VERSION ""

NS_ :

BS_:

BU_: BRAKE STEERING THROTTLE FAULT

BO_ 112 BRAKE_ENABLE: 8 BRAKE
 SG_ brake_enable_magic : 0|16@1+ (1,0) [0|0] "" BRAKE
 SG_ brake_enable_reserved : 16|48@1+ (1,0) [0|0] "" BRAKE

BO_ 113 BRAKE_DISABLE: 8 BRAKE
 SG_ brake_disable_magic : 0|16@1+ (1,0) [0|0] "" BRAKE
 SG_ brake_disable_reserved : 16|48@1+ (1,0) [0|0] "" BRAKE

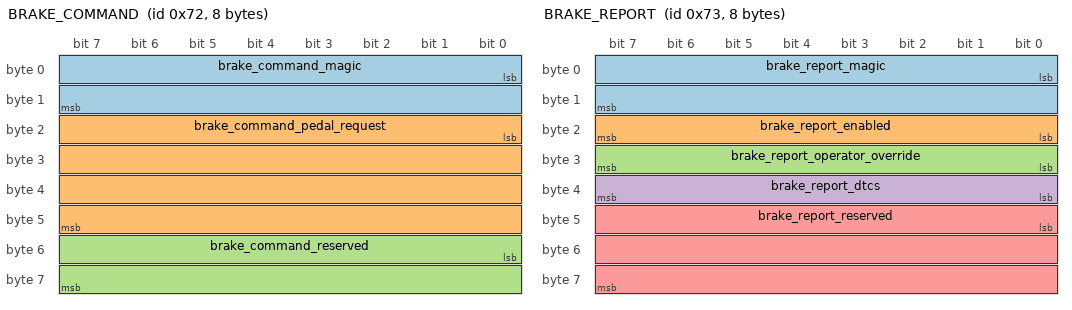
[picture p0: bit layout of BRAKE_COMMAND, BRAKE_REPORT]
BO_ 114 BRAKE_COMMAND: 8 BRAKE
 SG_ brake_command_magic : 0|16@1+ (1,0) [0|0] "" BRAKE
 SG_ brake_command_pedal_request : 16|32@1+ (1,0) [0|1] "" BRAKE
 SG_ brake_command_reserved : 48|16@1+ (1,0) [0|0] "" BRAKE

BO_ 115 BRAKE_REPORT: 8 BRAKE
 SG_ brake_report_magic : 0|16@1+ (1,0) [0|0] "" BRAKE
 SG_ brake_report_enabled : 16|8@1+ (1,0) [0|0] "" BRAKE
 SG_ brake_report_operator_override : 24|8@1+ (1,0) [0|0] "" BRAKE
 SG_ brake_report_dtcs : 32|8@1+ (1,0) [0|0] "" BRAKE
 SG_ brake_report_reserved : 40|24@1+ (1,0) [0|0] "" BRAKE

BO_ 128 STEERING_ENABLE: 8 STEERING
 SG_ steering_enable_magic : 0|16@1+ (1,0) [0|0] "" STEERING
 SG_ steering_enable_reserved : 16|48@1+ (1,0) [0|0] "" STEERING

BO_ 129 STEERING_DISABLE: 8 STEERING
 SG_ steering_disable_magic : 0|16@1+ (1,0) [0|0] "" STEERING
 SG_ steering_disable_reserved : 16|48@1+ (1,0) [0|0] "" STEERING

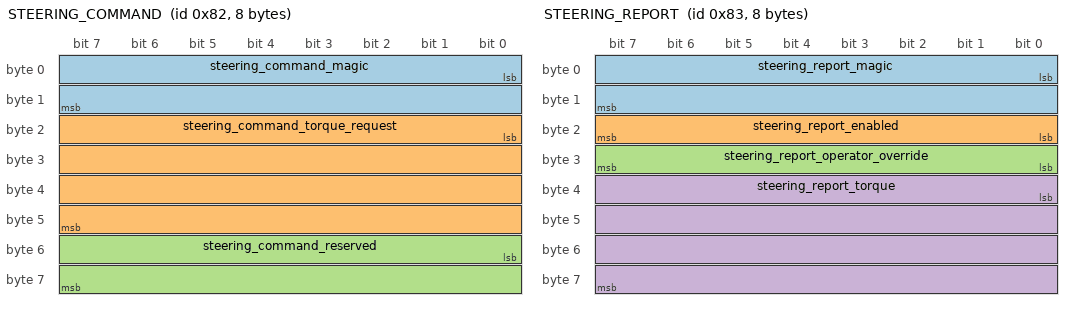
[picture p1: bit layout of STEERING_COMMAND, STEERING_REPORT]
BO_ 130 STEERING_COMMAND: 8 STEERING
 SG_ steering_command_magic : 0|16@1+ (1,0) [0|0] "" STEERING
 SG_ steering_command_torque_request : 16|32@1- (1,0) [-15|15] "" STEERING
 SG_ steering_command_reserved : 48|16@1+ (1,0) [0|0] "" STEERING

BO_ 131 STEERING_REPORT: 8 STEERING
 SG_ steering_report_magic : 0|16@1+ (1,0) [0|0] "" STEERING
 SG_ steering_report_enabled : 16|8@1+ (1,0) [0|0] "" STEERING
 SG_ steering_report_operator_override : 24|8@1+ (1,0) [0|0] "" STEERING
 SG_ steering_report_torque : 32|32@1- (0.001,0) [-1.0|1.0] "" STEERING

BO_ 144 THROTTLE_ENABLE: 8 THROTTLE
 SG_ throttle_enable_magic : 0|16@1+ (1,0) [0|0] "" THROTTLE
 SG_ throttle_enable_reserved : 16|48@1+ (1,0) [0|0] "" THROTTLE

BO_ 145 THROTTLE_DISABLE: 8 THROTTLE
 SG_ throttle_disable_magic : 0|16@1+ (1,0) [0|0] "" THROTTLE
 SG_ throttle_disable_reserved : 16|48@1+ (1,0) [0|0] "" THROTTLE

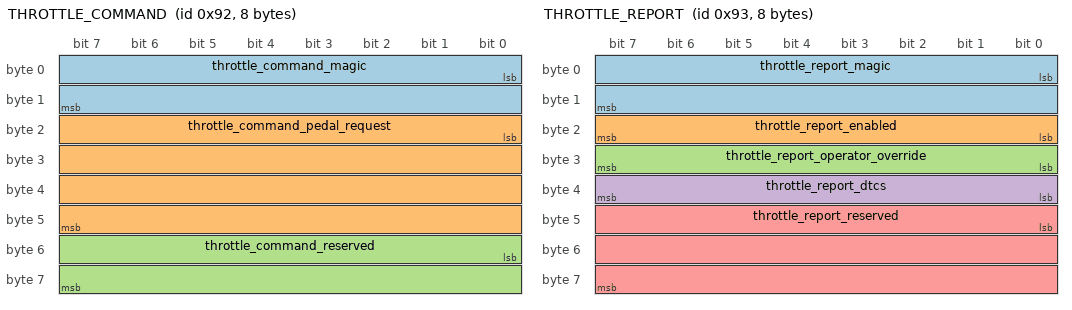
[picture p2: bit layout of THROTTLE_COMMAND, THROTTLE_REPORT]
BO_ 146 THROTTLE_COMMAND: 8 THROTTLE
 SG_ throttle_command_magic : 0|16@1+ (1,0) [0|0] "" THROTTLE
 SG_ throttle_command_pedal_request : 16|32@1- (1,0) [0|1] "" THROTTLE
 SG_ throttle_command_reserved : 48|16@1+ (1,0) [0|0] "" THROTTLE

BO_ 147 THROTTLE_REPORT: 8 THROTTLE
 SG_ throttle_report_magic : 0|16@1+ (1,0) [0|0] "" THROTTLE
 SG_ throttle_report_enabled : 16|8@1+ (1,0) [0|0] "" THROTTLE
 SG_ throttle_report_operator_override : 24|8@1+ (1,0) [0|0] "" THROTTLE
 SG_ throttle_report_dtcs : 32|8@1+ (1,0) [0|0] "" THROTTLE
 SG_ throttle_report_reserved : 40|24@1+ (1,0) [0|0] "" THROTTLE

BO_ 148 VELOCITY_TRAJECTORY: 8 THROTTLE
 SG_ velocity_trajectory_vel_start : 0|16@1- (1,0) [0|1] "" THROTTLE
 SG_ velocity_trajectory_acc_start : 16|32@1- (1,0) [0|1] "" THROTTLE
 SG_ velocity_trajectory_vel_end : 32|48@1- (1,0) [0|1] "" THROTTLE
 SG_ velocity_trajectory_acc_end : 48|64@1- (1,0) [0|1] "" THROTTLE

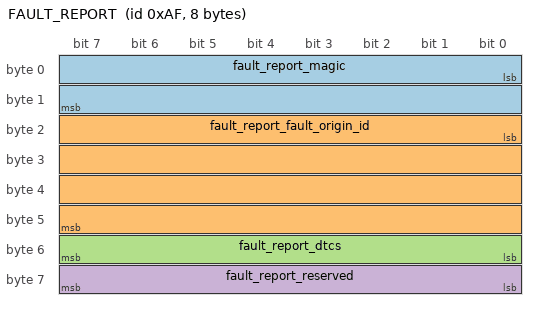
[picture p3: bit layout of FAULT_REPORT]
BO_ 175 FAULT_REPORT: 8 FAULT
 SG_ fault_report_magic : 0|16@1+ (1,0) [0|0] "" FAULT
 SG_ fault_report_fault_origin_id : 16|32@1+ (1,0) [0|0] "" FAULT
 SG_ fault_report_dtcs : 48|8@1+ (1,0) [0|0] "" FAULT
 SG_ fault_report_reserved : 56|8@1+ (1,0) [0|0] "" FAULT

CM_ BU_ BRAKE "The OSCC brake module";
CM_ BU_ STEERING "The OSCC steering module";
CM_ BU_ THROTTLE "The OSCC throttle module";
CM_ BU_ FAULT "The OSCC fault report";
SIG_VALTYPE_ 114 brake_command_pedal_request : 1;
SIG_VALTYPE_ 130 steering_command_torque_request : 1;
SIG_VALTYPE_ 146 throttle_command_pedal_request : 1;
